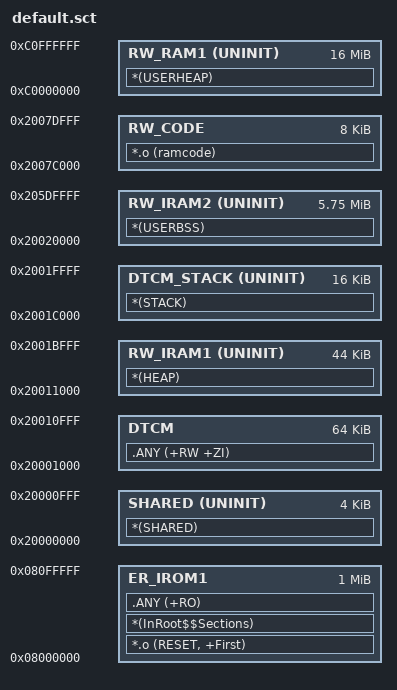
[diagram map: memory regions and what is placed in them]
; *************************************************************
; *** Scatter-Loading Description File generated by uVision ***
; *************************************************************

LR_IROM1 0x08000000 0x00100000  {    ; load region size_region
  ER_IROM1 0x08000000 0x00100000  {  ; load address = execution address
   *.o (RESET, +First)
   *(InRoot$$Sections)
   .ANY (+RO)
  }
;  RW_CODE 0x00000000 0x00002000  {  ; ITCM
  RW_CODE 0x2007c000 0x00002000  {  ; ITCM
   *.o (ramcode)
  }
  SHARED 0x20000000 UNINIT 0x00001000  {  ; DTCM
    *(SHARED)
  }
  DTCM 0x20001000 0x00010000  {  ; DTCM
   .ANY (+RW +ZI)
  }
; DBG ALGO NOW ON THE BOTTOM OF STACK
  DTCM_STACK 0x2001C000 UNINIT 0x00004000  {  ; DTCM
   *(STACK)
  }
  RW_IRAM1 0x20011000 UNINIT 0x0000B000  {  ; RW data
   *(HEAP)
  }
  RW_IRAM2 0x20020000 UNINIT 0x0005c0000  {  ; DTCM
   *(USERBSS)
  }
  RW_RAM1 0xC0000000 UNINIT 0x01000000  {  ; RW data
   *(USERHEAP)
  }
}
